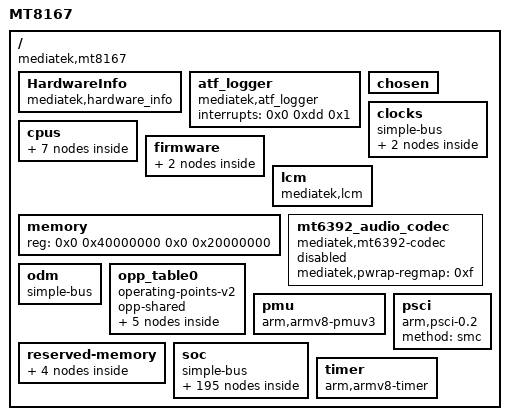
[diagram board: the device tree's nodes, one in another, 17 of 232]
/dts-v1/;

/ {
	#address-cells = <0x2>;
	#size-cells = <0x2>;
	compatible = "mediatek,mt8167";
	interrupt-parent = <0x1>;
	model = "MT8167";

	HardwareInfo {
		compatible = "mediatek,hardware_info";
		linux,phandle = <0xa5>;
		phandle = <0xa5>;
		status = "ok";
	};

	__symbols__ {
		CLUSTER_SLEEP_0 = "/cpus/idle-states/cluster-sleep-0";
		CPU_SLEEP_0_0 = "/cpus/idle-states/cpu-sleep-0-0";
		HardwareInfo = "/HardwareInfo";
		ac108gpio = "/soc/ac108gpio";
		accdet = "/soc/accdet@1001b000";
		afe = "/soc/audio-controller@11140000";
		alsps = "/soc/als_ps@0";
		android = "/firmware/android";
		apmixedsys = "/soc/apmixedsys@10018000";
		atf_reserved_memory = "/reserved-memory/atf-reserved-memory";
		audiotop = "/soc/audiotop@11140000";
		auxadc = "/soc/auxadc@11003000";
		bat_comm = "/soc/bat_comm";
		bat_meter = "/soc/bat_meter";
		btif = "/soc/btif@1100e000";
		chipid = "/soc/chipid@08000000";
		clk26m = "/clocks/clk26m";
		clk32k = "/clocks/clk32k";
		cluster0_opp = "/opp_table0";
		consys = "/soc/consys@18070000";
		cpu0 = "/cpus/cpu@0";
		cpu1 = "/cpus/cpu@1";
		cpu2 = "/cpus/cpu@2";
		cpu3 = "/cpus/cpu@3";
		ddrphy = "/soc/ddrphy@10211000";
		disp_aal = "/soc/disp_aal@1400e000";
		disp_ccorr = "/soc/disp_ccorr@1400d000";
		disp_color = "/soc/disp_color@1400c000";
		disp_dither = "/soc/disp_dither@14010000";
		disp_dpi0 = "/soc/disp_dpi0@14013000";
		disp_dpi1 = "/soc/disp_dpi1@14019000";
		disp_dsi0 = "/soc/disp_dsi0@14012000";
		disp_gamma = "/soc/disp_gamma@1400f000";
		disp_lvds_ana = "/soc/disp_lvds_ana@14018800";
		disp_lvds_tx = "/soc/disp_lvds_tx@1401a200";
		disp_ovl0 = "/soc/disp_ovl0@14007000";
		disp_pwm0 = "/soc/disp_pwm0@1100f000";
		disp_rdma0 = "/soc/disp_rdma0@14009000";
		disp_rdma1 = "/soc/disp_rdma1@1400a000";
		disp_wdma0 = "/soc/disp_wdma0@1400b000";
		dispsys = "/soc/mt8167-dispsys";
		dramc_nao = "/soc/dramc_nao@10206000";
		dramco = "/soc/dramco@10207000";
		emi = "/soc/emi@10205000";
		extd_drv = "/soc/extd_drv@0";
		firmware = "/firmware";
		flashlight_core = "/soc/flashlight_core";
		flashlights_lm3642 = "/soc/flashlights_lm3642";
		fstab = "/firmware/android/fstab";
		gce = "/soc/gce@1020a000";
		gic = "/soc/interrupt-controller@10310000";
		gyro = "/soc/gyroscope@0";
		hdmi0 = "/soc/hdmi@1401b000";
		i2c0 = "/soc/i2c@11009000";
		i2c1 = "/soc/i2c@1100a000";
		i2c2 = "/soc/i2c@1100b000";
		ice = "/soc/ice_debug";
		imgsys = "/soc/imgsys@15000000";
		infracfg = "/soc/infracfg@10001000";
		iommu = "/soc/m4u@10203000";
		isp_display = "/soc/isp_display";
		ispsys = "/soc/ispsys@15000000";
		kd_camera_hw1 = "/soc/camera1@15008000";
		kd_camera_hw2 = "/soc/camera2@15008000";
		keypad = "/soc/keypad@10002000";
		larb0 = "/soc/larb@14016000";
		larb1 = "/soc/larb@15001000";
		larb2 = "/soc/larb@16010000";
		lcm = "/lcm";
		lcm_gpio = "/soc/lcm_gpio@0";
		led0 = "/soc/led@0";
		led1 = "/soc/led@1";
		led2 = "/soc/led@2";
		led3 = "/soc/led@3";
		led4 = "/soc/led@4";
		led5 = "/soc/led@5";
		led6 = "/soc/led@6";
		mcucfg = "/soc/mcucfg@10200000";
		mdp_rdma = "/soc/mdp_rdma@14001000";
		mdp_rsz0 = "/soc/mdp_rsz0@14002000";
		mdp_rsz1 = "/soc/mdp_rsz1@14003000";
		mdp_tdshp = "/soc/mdp_tdshp@14006000";
		mdp_wdma = "/soc/mdp_wdma@14004000";
		mdp_wrot = "/soc/mdp_wrot@14005000";
		met_smi = "/soc/met_smi@14017000";
		mfg = "/soc/clark@13000000";
		mfg_2d = "/soc/mfgsys-2d";
		mfg_async = "/soc/mfgsys-async";
		mfgcfg = "/soc/mfgcfg@13ffe000";
		mipi_tx0 = "/soc/mipi_dphy@14018000";
		mm_mutex = "/soc/mm_mutex@14015000";
		mmc0 = "/soc/mmc@11120000";
		mmc1 = "/soc/mmc@11130000";
		mmc2 = "/soc/sdio@11170000";
		mmsys = "/soc/mmsys@14000000";
		mt6392_audio_codec = "/mt6392_audio_codec";
		mt6392_vadc18_reg = "/soc/pwrap@1000f000/mt6392/mt6392regulator/ldo_vadc18";
		mt6392_vaud22_reg = "/soc/pwrap@1000f000/mt6392/mt6392regulator/ldo_vaud22";
		mt6392_vaud28_reg = "/soc/pwrap@1000f000/mt6392/mt6392regulator/ldo_vaud28";
		mt6392_vcama_reg = "/soc/pwrap@1000f000/mt6392/mt6392regulator/ldo_vcama";
		mt6392_vcamaf_reg = "/soc/pwrap@1000f000/mt6392/mt6392regulator/ldo_vcamaf";
		mt6392_vcamd_reg = "/soc/pwrap@1000f000/mt6392/mt6392regulator/ldo_vcamd";
		mt6392_vcamio_reg = "/soc/pwrap@1000f000/mt6392/mt6392regulator/ldo_vcamio";
		mt6392_vcn18_reg = "/soc/pwrap@1000f000/mt6392/mt6392regulator/ldo_vcn18";
		mt6392_vcn35_reg = "/soc/pwrap@1000f000/mt6392/mt6392regulator/ldo_vcn35";
		mt6392_vcore_reg = "/soc/pwrap@1000f000/mt6392/mt6392regulator/buck_vcore";
		mt6392_vefuse_reg = "/soc/pwrap@1000f000/mt6392/mt6392regulator/ldo_vefuse";
		mt6392_vemc3v3_reg = "/soc/pwrap@1000f000/mt6392/mt6392regulator/ldo_vemc3v3";
		mt6392_vgp1_reg = "/soc/pwrap@1000f000/mt6392/mt6392regulator/ldo_vgp1";
		mt6392_vgp2_reg = "/soc/pwrap@1000f000/mt6392/mt6392regulator/ldo_vgp2";
		mt6392_vio18_reg = "/soc/pwrap@1000f000/mt6392/mt6392regulator/ldo_vio18";
		mt6392_vio28_reg = "/soc/pwrap@1000f000/mt6392/mt6392regulator/ldo_vio28";
		mt6392_vm25_reg = "/soc/pwrap@1000f000/mt6392/mt6392regulator/ldo_vm25";
		mt6392_vm_reg = "/soc/pwrap@1000f000/mt6392/mt6392regulator/ldo_vm";
		mt6392_vmc_reg = "/soc/pwrap@1000f000/mt6392/mt6392regulator/ldo_vmc";
		mt6392_vmch_reg = "/soc/pwrap@1000f000/mt6392/mt6392regulator/ldo_vmch";
		mt6392_vproc_reg = "/soc/pwrap@1000f000/mt6392/mt6392regulator/buck_vproc";
		mt6392_vsys_reg = "/soc/pwrap@1000f000/mt6392/mt6392regulator/buck_vsys";
		mt6392_vusb_reg = "/soc/pwrap@1000f000/mt6392/mt6392regulator/ldo_vusb";
		mt6392_vxo22_reg = "/soc/pwrap@1000f000/mt6392/mt6392regulator/ldo_vxo22";
		mt6392keys = "/soc/pwrap@1000f000/mt6392/mt6392keys";
		mt6392pmic = "/soc/pwrap@1000f000/mt6392/mt6392pmic";
		mt6392regulator = "/soc/pwrap@1000f000/mt6392/mt6392regulator";
		mtkfb = "/soc/mtkfb@0";
		nfi = "/soc/nfi@11001000";
		nfiecc = "/soc/nfiecc@11002000";
		odm = "/odm";
		pio = "/soc/pinctrl@10005000";
		pio6392 = "/soc/pwrap@1000f000/mt6392/pinctrl@c000";
		pmic = "/soc/pwrap@1000f000/mt6392";
		ptp_od = "/soc/ptp_od@1100d000";
		pwm = "/soc/pwm@11008000";
		pwrap = "/soc/pwrap@1000f000";
		reserved_memory = "/reserved-memory";
		scpsys = "/soc/scpsys@10006000";
		smi_common = "/soc/smi@14017000";
		spi = "/soc/spi@1100c000";
		sys_cirq = "/soc/sys_cirq@10202000";
		syscfg_pctl_a = "/soc/syscfg_pctl_a@10005000";
		sysirq = "/soc/intpol-controller@10200620";
		systracker = "/soc/systracker@1020b000";
		thermal = "/soc/thermal@1100d000";
		timer = "/soc/timer@10008000";
		topckgen = "/soc/topckgen@10000000";
		toprgu = "/soc/toprgu@10007000";
		touch = "/soc/touch@";
		typec = "/soc/pwrap@1000f000/mt6392/typec";
		uart0 = "/soc/uart0@11005000";
		uart0_gpio_def_cfg = "/soc/pinctrl@10005000/uart0gpiodefault";
		uart0_rx_clr_cfg = "/soc/pinctrl@10005000/uart0_rx_clear";
		uart0_rx_set_cfg = "/soc/pinctrl@10005000/uart0_rx_set";
		uart0_tx_clr_cfg = "/soc/pinctrl@10005000/uart0_tx_clear";
		uart0_tx_set_cfg = "/soc/pinctrl@10005000/uart0_tx_set";
		uart1 = "/soc/uart1@11006000";
		uart1_gpio_def_cfg = "/soc/pinctrl@10005000/uart1gpiodefault";
		uart1_rx_clr_cfg = "/soc/pinctrl@10005000/uart1_rx_clear";
		uart1_rx_set_cfg = "/soc/pinctrl@10005000/uart1_rx_set";
		uart1_tx_clr_cfg = "/soc/pinctrl@10005000/uart1_tx_clear";
		uart1_tx_set_cfg = "/soc/pinctrl@10005000/uart1_tx_set";
		uart2 = "/soc/uart2@11007000";
		uart2_gpio_def_cfg = "/soc/pinctrl@10005000/uart2gpiodefault";
		uart2_rx_clr_cfg = "/soc/pinctrl@10005000/uart2_rx_clear";
		uart2_rx_set_cfg = "/soc/pinctrl@10005000/uart2_rx_set";
		uart2_tx_clr_cfg = "/soc/pinctrl@10005000/uart2_tx_clear";
		uart2_tx_set_cfg = "/soc/pinctrl@10005000/uart2_tx_set";
		usb0 = "/soc/usb@11100000";
		usb1 = "/soc/usb@11190000";
		vdecsys = "/soc/vdecsys@16000000";
		vencsys = "/soc/vencsys@15000000";
		xo = "/soc/xo@10210000";
	};

	atf_logger {
		compatible = "mediatek,atf_logger";
		interrupts = <0x0 0xdd 0x1>;
	};

	chosen {
		bootargs = "console=ttyS0,921600n1 root=/dev/ram initrd=0x44000200,0x200000";
	};

	clocks {
		#address-cells = <0x2>;
		#size-cells = <0x2>;
		compatible = "simple-bus";
		ranges;

		clk26m {
			#clock-cells = <0x0>;
			clock-frequency = <0x18cba80>;
			compatible = "fixed-clock";
			linux,phandle = <0x30>;
			phandle = <0x30>;
		};

		clk32k {
			#clock-cells = <0x0>;
			clock-frequency = <0x7d00>;
			compatible = "fixed-clock";
			linux,phandle = <0xd>;
			phandle = <0xd>;
		};
	};

	cpus {
		#address-cells = <0x1>;
		#size-cells = <0x0>;

		cpu@0 {
			clock-frequency = "M|m";
			clock-names = "cpu", "intermediate", "armpll";
			clocks = <0x4 0x0 0x5 0x8 0x6 0x0>;
			compatible = "arm,cortex-a53";
			cpu-idle-states = <0x2 0x2 0x3 0x3 0x3>;
			device_type = "cpu";
			enable-method = "psci";
			linux,phandle = <0x8>;
			operating-points-v2 = <0x7>;
			phandle = <0x8>;
			reg = <0x0>;
		};

		cpu@1 {
			clock-frequency = "M|m";
			clock-names = "cpu", "intermediate", "armpll";
			clocks = <0x4 0x0 0x5 0x8 0x6 0x0>;
			compatible = "arm,cortex-a53";
			cpu-idle-states = <0x2 0x2 0x3 0x3 0x3>;
			device_type = "cpu";
			enable-method = "psci";
			linux,phandle = <0x9>;
			operating-points-v2 = <0x7>;
			phandle = <0x9>;
			reg = <0x1>;
		};

		cpu@2 {
			clock-frequency = "M|m";
			clock-names = "cpu", "intermediate", "armpll";
			clocks = <0x4 0x0 0x5 0x8 0x6 0x0>;
			compatible = "arm,cortex-a53";
			cpu-idle-states = <0x2 0x2 0x3 0x3 0x3>;
			device_type = "cpu";
			enable-method = "psci";
			linux,phandle = <0xa>;
			operating-points-v2 = <0x7>;
			phandle = <0xa>;
			reg = <0x2>;
		};

		cpu@3 {
			clock-frequency = "M|m";
			clock-names = "cpu", "intermediate", "armpll";
			clocks = <0x4 0x0 0x5 0x8 0x6 0x0>;
			compatible = "arm,cortex-a53";
			cpu-idle-states = <0x2 0x2 0x3 0x3 0x3>;
			device_type = "cpu";
			enable-method = "psci";
			linux,phandle = <0xb>;
			operating-points-v2 = <0x7>;
			phandle = <0xb>;
			reg = <0x3>;
		};

		idle-states {
			entry-method = "arm,psci";

			cluster-sleep-0 {
				arm,psci-suspend-param = <0x2010000>;
				compatible = "arm,idle-state";
				entry-latency-us = <0x320>;
				exit-latency-us = <0x3e8>;
				linux,phandle = <0x2>;
				min-residency-us = <0x7d0>;
				phandle = <0x2>;
			};

			cpu-sleep-0-0 {
				arm,psci-suspend-param = <0x10000>;
				compatible = "arm,idle-state";
				entry-latency-us = <0x258>;
				exit-latency-us = <0x258>;
				linux,phandle = <0x3>;
				min-residency-us = <0x4b0>;
				phandle = <0x3>;
			};
		};
	};

	firmware {
		linux,phandle = <0xa7>;
		phandle = <0xa7>;

		android {
			compatible = "android,firmware";
			linux,phandle = <0xa8>;
			phandle = <0xa8>;

			fstab {
				compatible = "android,fstab";
				linux,phandle = <0xa9>;
				phandle = <0xa9>;
			};
		};
	};

	lcm {
		compatible = "mediatek,lcm";
		linux,phandle = <0xa4>;
		phandle = <0xa4>;
	};

	memory {
		device_type = "memory";
		reg = <0x0 0x40000000 0x0 0x20000000>;
	};

	mt6392_audio_codec {
		compatible = "mediatek,mt6392-codec";
		linux,phandle = <0xa6>;
		mediatek,pwrap-regmap = <0xf>;
		phandle = <0xa6>;
		status = "disabled";
	};

	odm {
		compatible = "simple-bus";
		linux,phandle = <0xaa>;
		phandle = <0xaa>;
	};

	opp_table0 {
		compatible = "operating-points-v2";
		linux,phandle = <0x7>;
		opp-shared;
		phandle = <0x7>;

		opp00 {
			opp-hz = <0x0 0x23a4c180>;
			opp-microvolt = <0x118c30>;
		};

		opp01 {
			opp-hz = <0x0 0x2c8df1e0>;
			opp-microvolt = <0x118c30>;
		};

		opp02 {
			opp-hz = <0x0 0x3dfd2400>;
			opp-microvolt = <0x124f80>;
		};

		opp03 {
			opp-hz = <0x0 0x47498300>;
			opp-microvolt = <0x1312d0>;
		};

		opp04 {
			opp-hz = <0x0 0x4d7c6d00>;
			opp-microvolt = <0x13d620>;
		};
	};

	pmu {
		compatible = "arm,armv8-pmuv3", "arm,cortex-a7-pmu";
		interrupt-affinity = <0x8 0x9 0xa 0xb>;
		interrupts = <0x0 0x4 0x8 0x0 0x5 0x8 0x0 0x6 0x8 0x0 0x7 0x8>;
	};

	psci {
		compatible = "arm,psci-0.2";
		method = "smc";
	};

	reserved-memory {
		#address-cells = <0x2>;
		#size-cells = <0x2>;
		linux,phandle = <0x2e>;
		phandle = <0x2e>;
		ranges;

		atf-reserved-memory {
			compatible = "mediatek,mt8167-atf-reserved-memory";
			linux,phandle = <0x2f>;
			no-map;
			phandle = <0x2f>;
			reg = <0x0 0x54600000 0x0 0x30000>;
		};

		minirdump-reserved-memory {
			compatible = "mediatek,minirdump";
			reg = <0x0 0x544f0000 0x0 0x10000>;
		};

		pstore-reserved-memory {
			compatible = "mediatek,pstore";
			reg = <0x0 0x54410000 0x0 0xe0000>;
		};

		ram_console-reserved-memory {
			compatible = "mediatek,ram_console";
			reg = <0x0 0x54400000 0x0 0x10000>;
		};
	};

	soc {
		#address-cells = <0x2>;
		#size-cells = <0x2>;
		compatible = "simple-bus";
		ranges;

		BAT_NOTIFY {
			compatible = "mediatek,bat_notify";
		};

		ac108gpio {
			compatible = "MicArray_gpio";
			linux,phandle = <0x99>;
			phandle = <0x99>;
			reg_1v8_gpio = <0x24 0xc 0x1>;
			reg_3v3_gpio = <0x24 0xd 0x1>;
		};

		accdet@1001b000 {
			compatible = "mediatek,mt8167-accdet";
			linux,phandle = <0x50>;
			phandle = <0x50>;
			reg = <0x0 0x1001b000 0x0 0x1000>;
			status = "disabled";
		};

		als_ps@0 {
			compatible = "mediatek,als_ps";
			linux,phandle = <0x90>;
			phandle = <0x90>;
		};

		apmixedsys@10018000 {
			#clock-cells = <0x1>;
			compatible = "mediatek,mt8167-apmixedsys", "syscon";
			linux,phandle = <0x6>;
			phandle = <0x6>;
			reg = <0x0 0x10018000 0x0 0x710>;
		};

		audio-controller@11140000 {
			assigned-clock-parents = <0x5 0x29 0x5 0x2d 0x5 0x91 0x5 0x94>;
			assigned-clocks = <0x5 0xbb 0x5 0xbc 0x5 0xbd 0x5 0xbe>;
			clock-names = "top_pdn_audio", "apll12_div0", "apll12_div1", "apll12_div2", "apll12_div3", "apll12_div4", "apll12_div4b", "apll12_div5", "apll12_div5b", "apll12_div6", "spdif_in", "engen1", "engen2", "aud1", "aud2", "i2s0_m_sel", "i2s1_m_sel", "i2s2_m_sel", "i2s3_m_sel", "i2s4_m_sel", "i2s5_m_sel", "spdif_b_sel";
			clocks = <0x5 0x5b 0x5 0x95 0x5 0x96 0x5 0x97 0x5 0x98 0x5 0x99 0x5 0x9a 0x5 0x9b 0x5 0x9c 0x5 0x9d 0x5 0x8a 0x5 0x86 0x5 0x87 0x5 0x84 0x5 0x85 0x5 0xc0 0x5 0xc1 0x5 0xc2 0x5 0xc3 0x5 0xc4 0x5 0xc5 0x5 0xc6>;
			compatible = "mediatek,mt8167-afe-pcm";
			interrupts = <0x0 0x78 0x8>;
			linux,phandle = <0x68>;
			phandle = <0x68>;
			reg = <0x0 0x11140000 0x0 0x1000 0x0 0x11141000 0x0 0x9000>;
		};

		audiotop@11140000 {
			#clock-cells = <0x1>;
			compatible = "mediatek,mt8167-audiotop", "syscon";
			linux,phandle = <0x6d>;
			phandle = <0x6d>;
			reg = <0x0 0x11140000 0x0 0x1000>;
		};

		auxadc@11003000 {
			clock-names = "auxadc-main", "auxadc1", "auxadc2", "auxadc-tp";
			clocks = <0x5 0x5f 0x5 0x47 0x5 0x51 0x5 0x60>;
			compatible = "mediatek,mt8167-auxadc";
			interrupts = <0x0 0x4b 0x2>;
			linux,phandle = <0x23>;
			phandle = <0x23>;
			reg = <0x0 0x11003000 0x0 0x1000>;
		};

		barometer@0 {
			compatible = "mediatek,barometer";
		};

		bat_comm {
			compatible = "mediatek,battery";
			linux,phandle = <0x9d>;
			phandle = <0x9d>;
		};

		bat_meter {
			compatible = "mediatek,bat_meter";
			linux,phandle = <0x9c>;
			phandle = <0x9c>;
		};

		batchsensor@0 {
			compatible = "mediatek,batchsensor";
		};

		btcvsd@10001000 {
			compatible = "mediatek,audio_bt_cvsd";
			interrupts = <0x0 0xc2 0x8>;
			offset = <0xc00 0x2 0xfd0 0xfd4 0xfd8>;
			reg = <0x0 0x10001000 0x0 0x1000 0x0 0x18000000 0x0 0x10000 0x0 0x18080000 0x0 0x8000>;
		};

		btif@1100e000 {
			clock-names = "btifc", "apdmac";
			clocks = <0x5 0x4e 0x5 0x44>;
			compatible = "mediatek,btif";
			interrupts = <0x0 0x6b 0x8 0x0 0x5e 0x8 0x0 0x5f 0x8>;
			linux,phandle = <0x65>;
			phandle = <0x65>;
			reg = <0x0 0x1100e000 0x0 0x1000 0x0 0x11000380 0x0 0x80 0x0 0x11000400 0x0 0x80>;
		};

		camera1@15008000 {
			clock-names = "TOP_CAMTG_SEL", "TOP_CAM_MIPI_26M", "TOP_CAMTG", "TOP_CAM_TG_48M", "TOP_CAM_TG_208M";
			clocks = <0x5 0xa4 0x5 0x40 0x5 0x3d 0x5 0x28 0x5 0x1c>;
			compatible = "mediatek,mt8167-camera_hw";
			linux,phandle = <0x8c>;
			phandle = <0x8c>;
			reg = <0x0 0x15008000 0x0 0x1000>;
		};

		camera2@15008000 {
			compatible = "mediatek,mt8167-camera_hw2";
			linux,phandle = <0x8d>;
			phandle = <0x8d>;
			reg = <0x0 0x15008000 0x0 0x1000>;
		};

		chipid@08000000 {
			compatible = "mediatek,chipid";
			linux,phandle = <0x31>;
			phandle = <0x31>;
			reg = <0x0 0x8000000 0x0 0x4 0x0 0x8000004 0x0 0x4 0x0 0x8000008 0x0 0x4 0x0 0x800000c 0x0 0x4>;
		};

		clark@13000000 {
			clock-frequency = <0x17d78400>;
			clock-names = "mfg_mm_in_sel", "mfg_axi_in_sel", "mfg_slow_in_sel", "top_slow", "top_axi", "top_mm", "slow_clk26m", "bus_univpll_d24", "bus_mainpll_d11", "engine_csw_mux";
			clocks = <0x5 0xae 0x5 0xb9 0x5 0xba 0x5 0x83 0x5 0x82 0x5 0x3e 0x5 0x31 0x5 0x1e 0x5 0xc 0x5 0xa2>;
			compatible = "mediatek,mt8167-clark";
			interrupt-names = "RGX";
			interrupts = <0x0 0xb9 0x8>;
			linux,phandle = <0x69>;
			phandle = <0x69>;
			power-domains = <0x25 0x6>;
			reg = <0x0 0x13000000 0x0 0x80000 0x0 0x13ffe000 0x0 0x1000>;
		};

		consys@18070000 {
			compatible = "mediatek,mt8167-consys";
			interrupts = <0x0 0xc3 0x8 0x0 0xc5 0x8>;
			linux,phandle = <0x8e>;
			phandle = <0x8e>;
			power-domains = <0x25 0x3>;
			reg = <0x0 0x18070000 0x0 0x200 0x0 0x10000000 0x0 0x2000>;
			reset-names = "connsys";
			resets = <0x29 0xc>;
			status = "disabled";
		};

		ddrphy@10211000 {
			compatible = "mediatek,mt8167-ddrphy", "mediatek,ddrphy";
			linux,phandle = <0x57>;
			phandle = <0x57>;
			reg = <0x0 0x10211000 0x0 0x1000>;
		};

		devapc@10204000 {
			compatible = "mediatek,mt8167-devapc";
			interrupts = <0x0 0x72 0x8>;
			reg = <0x0 0x10204000 0x0 0x1000>;
		};

		devapc_ao@10010000 {
			compatible = "mediatek,mt8167-devapc_ao";
			reg = <0x0 0x10010000 0x0 0x1000>;
		};

		disp_aal@1400e000 {
			compatible = "mediatek,mt8167-disp_aal";
			interrupts = <0x0 0xa7 0x8>;
			linux,phandle = <0x7d>;
			phandle = <0x7d>;
			reg = <0x0 0x1400e000 0x0 0x1000>;
		};

		disp_ccorr@1400d000 {
			compatible = "mediatek,mt8167-disp_ccorr";
			interrupts = <0x0 0xa6 0x8>;
			linux,phandle = <0x7c>;
			phandle = <0x7c>;
			reg = <0x0 0x1400d000 0x0 0x1000>;
		};

		disp_color@1400c000 {
			compatible = "mediatek,mt8167-disp_color";
			interrupts = <0x0 0xa5 0x8>;
			linux,phandle = <0x7b>;
			phandle = <0x7b>;
			reg = <0x0 0x1400c000 0x0 0x1000>;
		};

		disp_dither@14010000 {
			compatible = "mediatek,mt8167-disp_dither";
			interrupts = <0x0 0xa9 0x8>;
			linux,phandle = <0x7f>;
			phandle = <0x7f>;
			reg = <0x0 0x14010000 0x0 0x1000>;
		};

		disp_dpi0@14013000 {
			compatible = "mediatek,mt8167-disp_dpi0";
			interrupts = <0x0 0xac 0x8>;
			linux,phandle = <0x81>;
			phandle = <0x81>;
			reg = <0x0 0x14013000 0x0 0x1000>;
		};

		disp_dpi1@14019000 {
			compatible = "mediatek,mt8167-disp_dpi1";
			interrupts = <0x0 0xae 0x8>;
			linux,phandle = <0x85>;
			phandle = <0x85>;
			reg = <0x0 0x14019000 0x0 0x1000>;
		};

		disp_dsi0@14012000 {
			compatible = "mediatek,mt8167-disp_dsi0";
			interrupts = <0x0 0xab 0x8>;
			linux,phandle = <0x80>;
			phandle = <0x80>;
			reg = <0x0 0x14012000 0x0 0x1000>;
		};

		disp_gamma@1400f000 {
			compatible = "mediatek,mt8167-disp_gamma";
			interrupts = <0x0 0xa8 0x8>;
			linux,phandle = <0x7e>;
			phandle = <0x7e>;
			reg = <0x0 0x1400f000 0x0 0x1000>;
		};

		disp_lvds_ana@14018800 {
			compatible = "mediatek,mt8167-disp_lvds_ana";
			linux,phandle = <0x84>;
			phandle = <0x84>;
			reg = <0x0 0x14018800 0x0 0x1c>;
		};

		disp_lvds_tx@1401a200 {
			compatible = "mediatek,mt8167-disp_lvds_tx";
			linux,phandle = <0x86>;
			phandle = <0x86>;
			reg = <0x0 0x1401a200 0x0 0x64>;
		};

		disp_ovl0@14007000 {
			compatible = "mediatek,mt8167-disp_ovl0";
			interrupts = <0x0 0xa0 0x8>;
			linux,phandle = <0x77>;
			phandle = <0x77>;
			reg = <0x0 0x14007000 0x0 0x1000>;
		};

		disp_pwm0@1100f000 {
			compatible = "mediatek,mt8167-disp_pwm";
			linux,phandle = <0x66>;
			phandle = <0x66>;
			reg = <0x0 0x1100f000 0x0 0x1000>;
		};

		disp_rdma0@14009000 {
			compatible = "mediatek,mt8167-disp_rdma0";
			interrupts = <0x0 0xa2 0x8>;
			linux,phandle = <0x78>;
			phandle = <0x78>;
			reg = <0x0 0x14009000 0x0 0x1000>;
		};

		disp_rdma1@1400a000 {
			compatible = "mediatek,mt8167-disp_rdma1";
			interrupts = <0x0 0xa3 0x8>;
			linux,phandle = <0x79>;
			phandle = <0x79>;
			reg = <0x0 0x1400a000 0x0 0x1000>;
		};

		disp_wdma0@1400b000 {
			compatible = "mediatek,mt8167-disp_wdma0";
			interrupts = <0x0 0xa4 0x8>;
			linux,phandle = <0x7a>;
			phandle = <0x7a>;
			reg = <0x0 0x1400b000 0x0 0x1000>;
		};

		dramc_nao@10206000 {
			compatible = "mediatek,mt8167-dramc_nao", "mediatek,dramc_nao";
			linux,phandle = <0x55>;
			phandle = <0x55>;
			reg = <0x0 0x10206000 0x0 0x1000>;
		};

		dramco@10207000 {
			compatible = "mediatek,mt8167-dramco";
			linux,phandle = <0x33>;
			phandle = <0x33>;
			reg = <0x0 0x10207000 0x0 0x1000>;
		};

		dumchar {
			compatible = "mediatek,mt8167-dummy_char";
		};

		emi@10205000 {
			compatible = "mediatek,mt8167-emi", "mediatek,emi";
			interrupts = <0x0 0x74 0x4>;
			linux,phandle = <0x52>;
			phandle = <0x52>;
			reg = <0x0 0x10205000 0x0 0x1000>;
		};

		extd_drv@0 {
			compatible = "mediatek,extd_dev";
			linux,phandle = <0x9e>;
			phandle = <0x9e>;
		};

		fhctl@10018f00 {
			compatible = "mediatek,mt8167-fhctl";
			reg = <0x0 0x10018f00 0x0 0x100>;
		};

		flashlight_core {
			compatible = "mediatek,flashlight_core";
			linux,phandle = <0x9f>;
			phandle = <0x9f>;
		};

		flashlights_lm3642 {
			compatible = "mediatek,flashlights_lm3642";
			linux,phandle = <0xa0>;
			phandle = <0xa0>;
		};

		g3d_iommu@13005000 {
			cell-index = <0x2>;
			compatible = "mediatek,mt8167-g3d_iommu";
			interrupts = <0x0 0xe2 0x8>;
			reg = <0x0 0x13005000 0x0 0x1000>;
		};

		gce@1020a000 {
			apxgpt2_count = <0x10008028>;
			audio_base = <0x11220000 0x12 0xffff0000>;
			buf_underrun_event_0 = <0x30>;
			buf_underrun_event_1 = <0x31>;
			clock-names = "MT_CG_INFRA_GCE", "MT_CG_DISP0_SMI_COMMON", "MT_CG_DISP0_SMI_LARB0", "MT_CG_DISP0_CAM_MDP", "MT_CG_DISP0_MDP_RDMA", "MT_CG_DISP0_MDP_RSZ0", "MT_CG_DISP0_MDP_RSZ1", "MT_CG_DISP0_MDP_TDSHP", "MT_CG_DISP0_MDP_WROT", "MT_CG_DISP0_MDP_WDMA";
			clocks = <0x5 0x64 0x13 0x0 0x13 0x1 0x13 0x2 0x13 0x3 0x13 0x4 0x13 0x5 0x13 0x6 0x13 0x8 0x13 0x7>;
			compatible = "mediatek,mt8167-gce";
			conn_peri_base = <0x18000000 0x7 0xffff0000>;
			disp_aal_frame_done = <0x20>;
			disp_aal_sof = <0xd>;
			disp_ccorr_frame_done = <0x1e>;
			disp_ccorr_sof = <0xb>;
			disp_color_frame_done = <0x1f>;
			disp_color_sof = <0xc>;
			disp_dither_base = <0x14010000 0x2 0xffff0000>;
			disp_dither_frame_done = <0x22>;
			disp_dither_sof = <0xf>;
			disp_dpi0_frame_done = <0x24>;
			disp_dpi1_frame_done = <0x25>;
			disp_gamma_frame_done = <0x21>;
			disp_gamma_sof = <0xe>;
			disp_mutex_reg = <0x14015000 0x1000>;
			disp_ovl0_frame_done = <0x19>;
			disp_ovl0_sof = <0x6>;
			disp_pwm0_sof = <0x11>;
			disp_rdma0_frame_done = <0x1b>;
			disp_rdma0_sof = <0x8>;
			disp_rdma1_frame_done = <0x1c>;
			disp_rdma1_sof = <0x9>;
			disp_ufoe_frame_done = <0x23>;
			disp_ufoe_sof = <0x10>;
			disp_wdma0_frame_done = <0x1d>;
			disp_wdma0_sof = <0xa>;
			g3d_config_base = <0x13000000 0x0 0xffff0000>;
			gcpu_base = <0x1020d000 0xf 0xffff0000>;
			imgsys_base = <0x15000000 0x4 0xffff0000>;
			infra_na3_base = <0x10030000 0xb 0xffff0000>;
			infra_na4_base = <0x10040000 0xc 0xffff0000>;
			interrupts = <0x0 0x7d 0x8 0x0 0x7e 0x8>;
			isp_frame_done_p2_0 = <0x43>;
			isp_frame_done_p2_1 = <0x42>;
			kp_base = <0x10010000 0x9 0xffff0000>;
			linux,phandle = <0x58>;
			mcucfg_base = <0x10200000 0xe 0xffff0000>;
			mdp_rdma0_frame_done = <0x12>;
			mdp_rdma0_sof = <0x0>;
			mdp_rsz0_frame_done = <0x13>;
			mdp_rsz0_sof = <0x1>;
			mdp_rsz1_frame_done = <0x14>;
			mdp_rsz1_sof = <0x2>;
			mdp_tdshp_frame_done = <0x15>;
			mdp_tdshp_sof = <0x3>;
			mdp_wdma_frame_done = <0x16>;
			mdp_wdma_sof = <0x4>;
			mdp_wrot_read_frame_done = <0x18>;
			mdp_wrot_sof = <0x5>;
			mdp_wrot_write_frame_done = <0x17>;
			mm_na_base = <0x14020000 0x3 0xffff0000>;
			mmsys_config_base = <0x14000000 0x1 0xffff0000>;
			msdc0_base = <0x11230000 0x13 0xffff0000>;
			msdc1_base = <0x11240000 0x14 0xffff0000>;
			msdc2_base = <0x11250000 0x15 0xffff0000>;
			msdc3_base = <0x11260000 0x16 0xffff0000>;
			phandle = <0x58>;
			pwm_sw_base = <0x1100f000 0x63 0xfffff000>;
			reg = <0x0 0x1020a000 0x0 0x1000>;
			scp_base = <0x10050000 0xd 0xffff0000>;
			scp_sram_base = <0x10020000 0xa 0xffff0000>;
			seninf_cam0_fifo_full = <0x49>;
			stream_done_0 = <0x26>;
			stream_done_1 = <0x27>;
			stream_done_2 = <0x28>;
			stream_done_3 = <0x29>;
			stream_done_4 = <0x2a>;
			stream_done_5 = <0x2b>;
			stream_done_6 = <0x2c>;
			stream_done_7 = <0x2d>;
			stream_done_8 = <0x2e>;
			stream_done_9 = <0x2f>;
			topckgen_base = <0x10000000 0x8 0xffff0000>;
			usb0_base = <0x11200000 0x10 0xffff0000>;
			usb_sif_base = <0x11210000 0x11 0xffff0000>;
			vdec_gcon_base = <0x16000000 0x5 0xffff0000>;
			venc_gcon_base = <0x17000000 0x6 0xffff0000>;
		};

		gps {
			compatible = "mediatek,gps";
		};

		gsensor@0 {
			compatible = "mediatek,gsensor";
		};

		gyroscope@0 {
			compatible = "mediatek,gyroscope";
			linux,phandle = <0x91>;
			phandle = <0x91>;
		};

		hacc@1000a000 {
			clock-names = "main", "second";
			clocks = <0x5 0x57 0x5 0x66>;
			compatible = "mediatek,hacc";
			reg = <0x0 0x1000a000 0x0 0x1000>;
		};

		hdmi@1401b000 {
			clock-names = "clk_ddc", "clk_cec_26m", "clk_cec_32k", "mmsys_hdmi_pixel", "mmsys_hdmi_pll", "mmsys_hdmi_audio", "mmsys_hdmi_spidif";
			clocks = <0x5 0x70 0x5 0x71 0x5 0x72 0x13 0x1e 0x13 0x21 0x13 0x20 0x13 0x1f>;
			compatible = "mediatek,mt8167-hdmitx";
			interrupts = <0x0 0x94 0x8>;
			linux,phandle = <0x87>;
			phandle = <0x87>;
			power-domains = <0x25 0x0>;
			reg = <0x0 0x1401b000 0x0 0x1000 0x0 0x11011000 0x0 0x10 0x0 0x1001a000 0x0 0xbc>;
			status = "disabled";
		};

		hwmsensor@0 {
			compatible = "mediatek,hwmsensor";
		};

		i2c@11009000 {
			#address-cells = <0x1>;
			#size-cells = <0x0>;
			clock-frequency = <0x61a80>;
			clock-names = "main-source", "main-sel", "main", "dma";
			clocks = <0x5 0x39 0x4 0x2 0x5 0x45 0x5 0x44>;
			compatible = "mediatek,mt8167-i2c";
			interrupts = <0x0 0x50 0x8>;
			linux,phandle = <0x5f>;
			phandle = <0x5f>;
			reg = <0x0 0x11009000 0x0 0x90 0x0 0x11000180 0x0 0x80>;
			status = "disabled";
		};

		i2c@1100a000 {
			#address-cells = <0x1>;
			#size-cells = <0x0>;
			clock-names = "main-source", "main-sel", "main", "dma";
			clocks = <0x5 0x39 0x4 0x3 0x5 0x46 0x5 0x44>;
			compatible = "mediatek,mt8167-i2c";
			interrupts = <0x0 0x51 0x8>;
			linux,phandle = <0x60>;
			phandle = <0x60>;
			reg = <0x0 0x1100a000 0x0 0x90 0x0 0x11000200 0x0 0x80>;
			status = "disabled";
		};

		i2c@1100b000 {
			#address-cells = <0x1>;
			#size-cells = <0x0>;
			clock-names = "main-source", "main-sel", "main", "dma";
			clocks = <0x5 0x39 0x4 0x4 0x5 0x52 0x5 0x44>;
			compatible = "mediatek,mt8167-i2c";
			interrupts = <0x0 0x52 0x8>;
			linux,phandle = <0x61>;
			phandle = <0x61>;
			reg = <0x0 0x1100b000 0x0 0x90 0x0 0x11000280 0x0 0x80>;
			status = "disabled";
		};

		ice_debug {
			clock-names = "ice_dbg";
			clocks = <0x5 0x4a>;
			compatible = "mediatek,mt8167-ice_debug", "mediatek,mt8173-ice_debug";
			linux,phandle = <0xa1>;
			phandle = <0xa1>;
		};

		imgsys@15000000 {
			#clock-cells = <0x1>;
			compatible = "mediatek,mt8167-imgsys", "syscon";
			linux,phandle = <0x27>;
			phandle = <0x27>;
			reg = <0x0 0x15000000 0x0 0x1000>;
		};

		infracfg@10001000 {
			#clock-cells = <0x1>;
			compatible = "mediatek,mt8167-infracfg", "syscon";
			linux,phandle = <0x4>;
			phandle = <0x4>;
			reg = <0x0 0x10001000 0x0 0x1000>;
		};

		interrupt-controller@10310000 {
			#interrupt-cells = <0x3>;
			compatible = "arm,gic-400";
			interrupt-controller;
			interrupt-parent = <0xc>;
			interrupts = <0x1 0x9 0xf04>;
			linux,phandle = <0xc>;
			phandle = <0xc>;
			reg = <0x0 0x10310000 0x0 0x1000 0x0 0x10320000 0x0 0x1000 0x0 0x10340000 0x0 0x2000 0x0 0x10360000 0x0 0x2000>;
		};

		intpol-controller@10200620 {
			#interrupt-cells = <0x3>;
			compatible = "mediatek,mt8167-sysirq", "mediatek,mt6577-sysirq";
			interrupt-controller;
			interrupt-parent = <0xc>;
			linux,phandle = <0x1>;
			phandle = <0x1>;
			reg = <0x0 0x10200620 0x0 0x20>;
		};

		isp_display {
			compatible = "mediatek,mt8167-isp_display";
			linux,phandle = <0x89>;
			phandle = <0x89>;
		};

		isp_pipemgr {
			compatible = "mediatek,mt8167-isp_pipemgr";
		};

		isp_sysram {
			compatible = "mediatek,mt8167-isp_sysram";
		};

		ispsys@15000000 {
			clock-names = "IMG_LARB_SMI", "IMG_CAM_SMI", "IMG_CAM_CAM", "IMG_SEN_TG", "IMG_SEN_CAM", "MM_SMI_COMMON";
			clocks = <0x27 0x0 0x27 0x1 0x27 0x2 0x27 0x3 0x27 0x4 0x13 0x0>;
			compatible = "mediatek,mt8167-ispsys";
			interrupts = <0x0 0xb4 0x8 0x0 0xb7 0x8>;
			linux,phandle = <0x8a>;
			mediatek,smilarb = <0x11>;
			phandle = <0x8a>;
			reg = <0x0 0x15004000 0x0 0x9000 0x0 0x15000000 0x0 0x10000 0x0 0x10011000 0x0 0x3000>;
		};

		keypad@10002000 {
			compatible = "mediatek,mt8167-keypad";
			interrupts = <0x0 0x95 0x2>;
			linux,phandle = <0x4f>;
			phandle = <0x4f>;
			reg = <0x0 0x10002000 0x0 0x1000>;
		};

		larb@14016000 {
			clock-names = "apb", "smi";
			clocks = <0x13 0x1 0x13 0x1>;
			compatible = "mediatek,mt8167-smi-larb";
			linux,phandle = <0x10>;
			mediatek,larbid = <0x0>;
			mediatek,smi = <0x26>;
			phandle = <0x10>;
			power-domains = <0x25 0x0>;
			reg = <0x0 0x14016000 0x0 0x1000>;
		};

		larb@15001000 {
			clock-names = "apb", "smi";
			clocks = <0x27 0x0 0x27 0x0>;
			compatible = "mediatek,mt8167-smi-larb";
			linux,phandle = <0x11>;
			mediatek,larbid = <0x1>;
			mediatek,smi = <0x26>;
			phandle = <0x11>;
			power-domains = <0x25 0x2>;
			reg = <0x0 0x15001000 0x0 0x10000>;
		};

		larb@16010000 {
			clock-names = "apb", "smi";
			clocks = <0x28 0x0 0x28 0x1>;
			compatible = "mediatek,mt8167-smi-larb";
			linux,phandle = <0x12>;
			mediatek,larbid = <0x2>;
			mediatek,smi = <0x26>;
			phandle = <0x12>;
			power-domains = <0x25 0x1>;
			reg = <0x0 0x16010000 0x0 0x1000>;
		};

		lcm_gpio@0 {
			compatible = "mediatek,I2C_LCD_BIAS";
			lcm-supply = <0x2b>;
			lcm_gpio_enn = <0x24 0x14 0x0>;
			lcm_gpio_te = <0x24 0x43 0x0>;
			lcm_rst_pin = <0x24 0x42 0x0>;
			linux,phandle = <0x9b>;
			phandle = <0x9b>;
			status = "okay";
		};

		led@0 {
			compatible = "mediatek,red";
			data = <0x0>;
			led_mode = <0x0>;
			linux,phandle = <0x92>;
			phandle = <0x92>;
			pwm_config = <0x0 0x0 0x0 0x0 0x0>;
		};

		led@1 {
			compatible = "mediatek,green";
			data = <0x0>;
			led_mode = <0x0>;
			linux,phandle = <0x93>;
			phandle = <0x93>;
			pwm_config = <0x0 0x0 0x0 0x0 0x0>;
		};

		led@2 {
			compatible = "mediatek,blue";
			data = <0x0>;
			led_mode = <0x0>;
			linux,phandle = <0x94>;
			phandle = <0x94>;
			pwm_config = <0x0 0x0 0x0 0x0 0x0>;
		};

		led@3 {
			compatible = "mediatek,jogball-backlight";
			data = <0x0>;
			led_mode = <0x0>;
			linux,phandle = <0x95>;
			phandle = <0x95>;
			pwm_config = <0x0 0x0 0x0 0x0 0x0>;
		};

		led@4 {
			compatible = "mediatek,keyboard-backlight";
			data = <0x0>;
			led_mode = <0x0>;
			linux,phandle = <0x96>;
			phandle = <0x96>;
			pwm_config = <0x0 0x0 0x0 0x0 0x0>;
		};

		led@5 {
			compatible = "mediatek,button-backlight";
			data = <0x0>;
			led_mode = <0x0>;
			linux,phandle = <0x97>;
			phandle = <0x97>;
			pwm_config = <0x0 0x0 0x0 0x0 0x0>;
		};

		led@6 {
			compatible = "mediatek,lcd-backlight";
			data;
			led_mode = <0x5>;
			linux,phandle = <0x98>;
			phandle = <0x98>;
			pwm_config = <0x0 0x0 0x0 0x0 0x0>;
		};

		m4u@10203000 {
			#iommu-cells = <0x1>;
			cell-index = <0x0>;
			compatible = "mediatek,mt8167-m4u";
			interrupts = <0x0 0x79 0x8>;
			linux,phandle = <0x2d>;
			mediatek,larbs = <0x10 0x11 0x12>;
			phandle = <0x2d>;
			reg = <0x0 0x10203000 0x0 0x1000>;
		};

		mcucfg@10200000 {
			compatible = "mediatek,mt8167-mcucfg", "mediatek,mcucfg", "syscon";
			linux,phandle = <0x51>;
			phandle = <0x51>;
			reg = <0x0 0x10200000 0x0 0x2000>;
		};

		mdp_rdma@14001000 {
			compatible = "mediatek,mt8167-mdp_rdma";
			interrupts = <0x0 0x9a 0x8>;
			linux,phandle = <0x70>;
			phandle = <0x70>;
			reg = <0x0 0x14001000 0x0 0x1000>;
		};

		mdp_rsz0@14002000 {
			compatible = "mediatek,mt8167-mdp_rsz0";
			interrupts = <0x0 0x9b 0x8>;
			linux,phandle = <0x71>;
			phandle = <0x71>;
			reg = <0x0 0x14002000 0x0 0x1000>;
		};

		mdp_rsz1@14003000 {
			compatible = "mediatek,mt8167-mdp_rsz1";
			interrupts = <0x0 0x9c 0x8>;
			linux,phandle = <0x72>;
			phandle = <0x72>;
			reg = <0x0 0x14003000 0x0 0x1000>;
		};

		mdp_tdshp@14006000 {
			compatible = "mediatek,mdp_tdshp";
			interrupts = <0x0 0x9d 0x8>;
			linux,phandle = <0x75>;
			phandle = <0x75>;
			reg = <0x0 0x14006000 0x0 0x1000>;
		};

		mdp_wdma@14004000 {
			compatible = "mediatek,mt8167-mdp_wdma";
			interrupts = <0x0 0x9e 0x8>;
			linux,phandle = <0x73>;
			phandle = <0x73>;
			reg = <0x0 0x14004000 0x0 0x1000>;
		};

		mdp_wrot@14005000 {
			compatible = "mediatek,mt8167-mdp_wrot";
			interrupts = <0x0 0x9f 0x8>;
			linux,phandle = <0x74>;
			phandle = <0x74>;
			reg = <0x0 0x14005000 0x0 0x1000>;
		};

		met_smi@14017000 {
			clock-names = "smi-common", "smi-larb0", "img-larb1", "vdec-larb2";
			clocks = <0x13 0x0 0x13 0x1 0x27 0x0 0x28 0x0>;
			compatible = "mediatek,met_smi";
			linux,phandle = <0x88>;
			phandle = <0x88>;
			reg = <0x0 0x14017000 0x0 0x1000 0x0 0x14016000 0x0 0x1000 0x0 0x15001000 0x0 0x1000 0x0 0x16010000 0x0 0x1000>;
		};

		mfgcfg@13ffe000 {
			#clock-cells = <0x1>;
			compatible = "mediatek,mt8167-mfgcfg", "syscon";
			linux,phandle = <0x6a>;
			phandle = <0x6a>;
			reg = <0x0 0x13ffe000 0x0 0x1000>;
		};

		mfgsys-2d {
			compatible = "mediatek,mt8167-mfg-2d";
			linux,phandle = <0xa3>;
			phandle = <0xa3>;
			power-domains = <0x25 0x5>;
		};

		mfgsys-async {
			compatible = "mediatek,mt8167-mfg-async";
			linux,phandle = <0xa2>;
			phandle = <0xa2>;
			power-domains = <0x25 0x4>;
		};

		mipi_dphy@14018000 {
			compatible = "mediatek,mt8167-disp_mipi_tx";
			linux,phandle = <0x83>;
			phandle = <0x83>;
			reg = <0x0 0x14018000 0x0 0x90>;
		};

		mm_mutex@14015000 {
			compatible = "mediatek,mt8167-disp_mutex";
			interrupts = <0x0 0x99 0x8>;
			linux,phandle = <0x82>;
			phandle = <0x82>;
			reg = <0x0 0x14015000 0x0 0x1000>;
		};

		mmc@11120000 {
			clock-names = "source", "hclk", "source_cg";
			clocks = <0x5 0x53 0x5 0xa1 0x5 0xd9>;
			compatible = "mediatek,mt8167-mmc";
			interrupts = <0x0 0x4e 0x8>;
			linux,phandle = <0x6b>;
			phandle = <0x6b>;
			reg = <0x0 0x11120000 0x0 0x1000>;
			status = "disabled";
		};

		mmc@11130000 {
			clock-names = "source", "hclk", "source_cg";
			clocks = <0x5 0x54 0x5 0xa1 0x5 0xda>;
			compatible = "mediatek,mt8167-mmc";
			interrupts = <0x0 0x4f 0x8>;
			linux,phandle = <0x6c>;
			phandle = <0x6c>;
			reg = <0x0 0x11130000 0x0 0x1000>;
			status = "disabled";
		};

		mmsys@14000000 {
			#clock-cells = <0x1>;
			compatible = "mediatek,mt8167-mmsys", "syscon";
			linux,phandle = <0x13>;
			phandle = <0x13>;
			reg = <0x0 0x14000000 0x0 0x1000>;
		};

		msensor@0 {
			compatible = "mediatek,msensor";
		};

		mt8167-dispsys {
			clock-names = "MMSYS_CLK_FAKE_ENG", "MMSYS_CLK_DISP_OVL0", "MMSYS_CLK_DISP_RDMA0", "MMSYS_CLK_DISP_RDMA1", "MMSYS_CLK_DISP_WDMA0", "MMSYS_CLK_DISP_COLOR", "MMSYS_CLK_DISP_CCORR", "MMSYS_CLK_DISP_AAL", "MMSYS_CLK_DISP_GAMMA", "MMSYS_CLK_DISP_DITHER", "MMSYS_CLK_DISP_UFOE", "MMSYS_CLK_TOP_PWM_MM", "MMSYS_CLK_DISP_PWM", "MMSYS_CLK_DISP_PWM26M", "MMSYS_CLK_DSI_ENGINE", "MMSYS_CLK_DSI_DIGITAL", "MMSYS_CLK_DPI0_PIXEL", "MMSYS_CLK_DPI0_ENGINE", "MMSYS_CLK_LVDS_PIXEL", "MMSYS_CLK_LVDS_CTS", "MMSYS_CLK_DPI1_PIXEL", "MMSYS_CLK_DPI1_ENGINE", "MMSYS_CLK_TOP_MIPI_26M", "MMSYS_CLK_TOP_MIPI_26M_DBG", "MMSYS_CLK_TOP_RG_FDPI0", "MMSYS_CLK_MUX_DPI0_SEL", "MMSYS_APMIXED_LVDSPLL", "MMSYS_CLK_MUX_LVDSPLL_D2", "MMSYS_CLK_MUX_LVDSPLL_D4", "MMSYS_CLK_MUX_LVDSPLL_D8", "MMSYS_CLK_TOP_RG_FDPI1", "MMSYS_CLK_MUX_DPI1_SEL", "MMSYS_APMIXED_TVDPLL", "MMSYS_CLK_MUX_TVDPLL_D2", "MMSYS_CLK_MUX_TVDPLL_D4", "MMSYS_CLK_MUX_TVDPLL_D8", "MMSYS_CLK_MUX_TVDPLL_D16", "MMSYS_CLK_PWM_SEL", "TOP_UNIVPLL_D12";
			clocks = <0x13 0x9 0x13 0xa 0x13 0xb 0x13 0xc 0x13 0xd 0x13 0xe 0x13 0xf 0x13 0x10 0x13 0x11 0x13 0x12 0x13 0x13 0x5 0x3c 0x13 0x14 0x13 0x15 0x13 0x16 0x13 0x17 0x13 0x19 0x13 0x18 0x13 0x1a 0x13 0x1b 0x13 0x1d 0x13 0x1c 0x5 0x33 0x5 0x40 0x5 0x80 0x5 0xb7 0x6 0x7 0x5 0x25 0x5 0x26 0x5 0x27 0x5 0x81 0x5 0xb8 0x6 0x6 0x5 0x35 0x5 0x36 0x5 0x37 0x5 0x38 0x5 0xc7 0x5 0x1d>;
			compatible = "mediatek,mt8167-dispsys";
			linux,phandle = <0x76>;
			mediatek,larb = <0x10>;
			phandle = <0x76>;
		};

		mt_soc_btcvsd_rx_pcm@10001000 {
			compatible = "mediatek,mt_soc_btcvsd_rx_pcm";
		};

		mt_soc_btcvsd_tx_pcm@10001000 {
			compatible = "mediatek,mt_soc_btcvsd_tx_pcm";
		};

		mtee {
			clock-names = "GCPU", "TRNG", "IMG_CLK", "SMI_COMMON", "IMG_SMI";
			clocks = <0x5 0x7b 0x5 0x65 0x27 0x5 0x13 0x0 0x27 0x0>;
			compatible = "mediatek,mtee";
			pm-devs = <0x11 0x26>;
			pm-names = "isp", "disp";
		};

		mtgpufreq {
			compatible = "mediatek,mt8167-gpufreq";
			reg-vgpu-supply = <0x2c>;
		};

		mtkfb@0 {
			compatible = "mediatek,MTKFB";
			linux,phandle = <0x9a>;
			mediatek,larb = <0x10>;
			phandle = <0x9a>;
		};

		nfi@11001000 {
			clock-names = "nfi_hclk", "nfiecc_bclk", "nfi_bclk", "nfi_rgecc", "nfi_2xclk", "nfi_1xclk", "nfi_1xpad_sel", "nfi_2xpad_sel", "nfiecc_sel", "nfiecc_csw_sel", "infra_ahb", "clk_26m", "main_d4", "main_d5", "main_d6", "main_d7", "main_d8", "main_d10", "main_d12";
			clocks = <0x5 0x63 0x5 0x49 0x5 0x48 0x5 0x8e 0x5 0x55 0x5 0x3a 0x5 0xad 0x5 0xac 0x5 0xce 0x5 0xcd 0x5 0xa1 0x5 0x31 0x5 0x9 0x5 0x11 0x5 0xf 0x5 0x15 0x5 0xa 0x5 0x12 0x5 0x10>;
			compatible = "mediatek,mt8167-nfi";
			interrupts = <0x0 0x57 0x8>;
			linux,phandle = <0x59>;
			phandle = <0x59>;
			reg = <0x0 0x11001000 0x0 0x1000>;
			status = "disabled";
		};

		nfiecc@11002000 {
			compatible = "mediatek,mt8167-nfiecc";
			interrupts = <0x0 0x56 0x8>;
			linux,phandle = <0x5a>;
			phandle = <0x5a>;
			reg = <0x0 0x11002000 0x0 0x1000>;
			status = "disabled";
		};

		orientation@0 {
			compatible = "mediatek,orientation";
		};

		pinctrl@10005000 {
			#gpio-cells = <0x2>;
			#interrupt-cells = <0x2>;
			compatible = "mediatek,mt8167-pinctrl";
			gpio-controller;
			interrupt-controller;
			interrupts = <0x0 0x86 0x4>;
			linux,phandle = <0x24>;
			mediatek,pctl-regmap = <0xe>;
			phandle = <0x24>;
			pins-are-numbered;
			reg = <0x0 0x1000b000 0x0 0x1000>;

			uart0_rx_clear {
				linux,phandle = <0x16>;
				phandle = <0x16>;

				pins_cmd_dat {
					output-high;
					pinmux = <0x3e00>;
					slew-rate = <0x1>;
				};
			};

			uart0_rx_set {
				linux,phandle = <0x15>;
				phandle = <0x15>;

				pins_cmd_dat {
					bias-pull-up;
					input-enable;
					pinmux = <0x3e01>;
				};
			};

			uart0_tx_clear {
				linux,phandle = <0x18>;
				phandle = <0x18>;

				pins_cmd_dat {
					output-high;
					pinmux = <0x3f00>;
					slew-rate = <0x1>;
				};
			};

			uart0_tx_set {
				linux,phandle = <0x17>;
				phandle = <0x17>;

				pins_cmd_dat {
					pinmux = <0x3f01>;
				};
			};

			uart0gpiodefault {
				linux,phandle = <0x14>;
				phandle = <0x14>;

				pins_rx {
					bias-pull-up;
					input-enable;
					pinmux = <0x3e01>;
				};

				pins_tx {
					pinmux = <0x3f01>;
				};
			};

			uart1_rx_clear {
				linux,phandle = <0x1b>;
				phandle = <0x1b>;

				pins_cmd_dat {
					output-high;
					pinmux = <0x4000>;
					slew-rate = <0x1>;
				};
			};

			uart1_rx_set {
				linux,phandle = <0x1a>;
				phandle = <0x1a>;

				pins_cmd_dat {
					pinmux = <0x4001>;
				};
			};

			uart1_tx_clear {
				linux,phandle = <0x1d>;
				phandle = <0x1d>;

				pins_cmd_dat {
					output-high;
					pinmux = <0x4100>;
					slew-rate = <0x1>;
				};
			};

			uart1_tx_set {
				linux,phandle = <0x1c>;
				phandle = <0x1c>;

				pins_cmd_dat {
					pinmux = <0x4101>;
				};
			};

			uart1gpiodefault {
				linux,phandle = <0x19>;
				phandle = <0x19>;
			};

			uart2_rx_clear {
				linux,phandle = <0x20>;
				phandle = <0x20>;

				pins_cmd_dat {
					output-high;
					pinmux = <0x2200>;
					slew-rate = <0x1>;
				};
			};

			uart2_rx_set {
				linux,phandle = <0x1f>;
				phandle = <0x1f>;

				pins_cmd_dat {
					pinmux = <0x2201>;
				};
			};

			uart2_tx_clear {
				linux,phandle = <0x22>;
				phandle = <0x22>;

				pins_cmd_dat {
					output-high;
					pinmux = <0x2300>;
					slew-rate = <0x1>;
				};
			};

			uart2_tx_set {
				linux,phandle = <0x21>;
				phandle = <0x21>;

				pins_cmd_dat {
					pinmux = <0x2301>;
				};
			};

			uart2gpiodefault {
				linux,phandle = <0x1e>;
				phandle = <0x1e>;
			};
		};

		pseudo-m4u {
			compatible = "mediatek,mt8167-pseudo-m4u";
			iommus = <0x2d 0x1>;
		};

		pseudo-m4u-larb0 {
			compatible = "mediatek,mt8167-pseudo-port-m4u";
			iommus = <0x2d 0x0 0x2d 0x1 0x2d 0x2 0x2d 0x3 0x2d 0x4 0x2d 0x5 0x2d 0x5 0x2d 0x6 0x2d 0x7>;
			mediatek,larbid = <0x0>;
		};

		pseudo-m4u-larb1 {
			compatible = "mediatek,mt8167-pseudo-port-m4u";
			iommus = <0x2d 0x8 0x2d 0x9 0x2d 0xa 0x2d 0xb 0x2d 0xc 0x2d 0xd 0x2d 0xe 0x2d 0xf 0x2d 0x10 0x2d 0x11 0x2d 0x12 0x2d 0x13 0x2d 0x14>;
			mediatek,larbid = <0x1>;
		};

		pseudo-m4u-larb2 {
			compatible = "mediatek,mt8167-pseudo-port-m4u";
			iommus = <0x2d 0x15 0x2d 0x16 0x2d 0x17 0x2d 0x18 0x2d 0x19 0x2d 0x1a 0x2d 0x1b>;
			mediatek,larbid = <0x2>;
		};

		ptp_od@1100d000 {
			compatible = "mediatek,mt8167-ptp_od";
			interrupts = <0x0 0x53 0x8>;
			linux,phandle = <0x64>;
			phandle = <0x64>;
			reg = <0x0 0x1100d000 0x0 0x1000>;
		};

		pwm@11008000 {
			clock-names = "PWM-main", "PWM1-main", "PWM2-main", "PWM3-main", "PWM4-main", "PWM5-main";
			clocks = <0x5 0x68 0x5 0x69 0x5 0x6a 0x5 0x6b 0x5 0x6c 0x5 0x6d>;
			compatible = "mediatek,mt8167-pwm";
			interrupts = <0x0 0x4c 0x8>;
			linux,phandle = <0x5e>;
			phandle = <0x5e>;
			reg = <0x0 0x11008000 0x0 0x1000>;
		};

		pwrap@1000f000 {
			clock-names = "spi", "wrap";
			clocks = <0x5 0x5e 0x5 0x56>;
			compatible = "mediatek,mt8167-pwrap";
			interrupts = <0x0 0xcc 0x8>;
			linux,phandle = <0xf>;
			phandle = <0xf>;
			reg = <0x0 0x1000f000 0x0 0x1000>;
			reg-names = "pwrap";
			status = "okay";

			mt6392 {
				compatible = "mediatek,mt6392";
				linux,phandle = <0x34>;
				mediatek,system-power-controller;
				phandle = <0x34>;

				mt6392keys {
					compatible = "mediatek,mt6392-keys";
					linux,phandle = <0x35>;
					mediatek,long-press-duration = <0x1>;
					mediatek,long-press-mode = <0x1>;
					mediatek,pwrkey-code = <0x74>;
					phandle = <0x35>;
				};

				mt6392pmic {
					compatible = "mediatek,mt6392-pmic";
					linux,phandle = <0x36>;
					phandle = <0x36>;
				};

				mt6392regulator {
					compatible = "mediatek,mt6392-regulator";
					linux,phandle = <0x37>;
					phandle = <0x37>;

					buck_vcore {
						linux,phandle = <0x2c>;
						phandle = <0x2c>;
						regulator-always-on;
						regulator-boot-on;
						regulator-max-microvolt = <0x149970>;
						regulator-min-microvolt = <0xaae60>;
						regulator-name = "vcore";
						regulator-ramp-delay = <0x30d4>;
					};

					buck_vproc {
						linux,phandle = <0x38>;
						phandle = <0x38>;
						regulator-always-on;
						regulator-boot-on;
						regulator-max-microvolt = <0x149970>;
						regulator-min-microvolt = <0xaae60>;
						regulator-name = "vproc";
						regulator-ramp-delay = <0x30d4>;
					};

					buck_vsys {
						linux,phandle = <0x39>;
						phandle = <0x39>;
						regulator-always-on;
						regulator-boot-on;
						regulator-max-microvolt = <0x2d95ec>;
						regulator-min-microvolt = <0x155cc0>;
						regulator-name = "vsys";
						regulator-ramp-delay = <0x61a8>;
					};

					ldo_vadc18 {
						linux,phandle = <0x3e>;
						phandle = <0x3e>;
						regulator-always-on;
						regulator-boot-on;
						regulator-enable-ramp-delay = <0x108>;
						regulator-max-microvolt = <0x1b7740>;
						regulator-min-microvolt = <0x1b7740>;
						regulator-name = "vadc18";
					};

					ldo_vaud22 {
						linux,phandle = <0x3b>;
						phandle = <0x3b>;
						regulator-always-on;
						regulator-boot-on;
						regulator-enable-ramp-delay = <0x108>;
						regulator-max-microvolt = <0x2191c0>;
						regulator-min-microvolt = <0x1b7740>;
						regulator-name = "vaud22";
					};

					ldo_vaud28 {
						linux,phandle = <0x3d>;
						phandle = <0x3d>;
						regulator-always-on;
						regulator-boot-on;
						regulator-enable-ramp-delay = <0x108>;
						regulator-max-microvolt = <0x2ab980>;
						regulator-min-microvolt = <0x2ab980>;
						regulator-name = "vaud28";
					};

					ldo_vcama {
						linux,phandle = <0x3c>;
						phandle = <0x3c>;
						regulator-enable-ramp-delay = <0x108>;
						regulator-max-microvolt = <0x2ab980>;
						regulator-min-microvolt = <0x2ab980>;
						regulator-name = "vcama";
					};

					ldo_vcamaf {
						linux,phandle = <0x47>;
						phandle = <0x47>;
						regulator-enable-ramp-delay = <0x108>;
						regulator-max-microvolt = <0x325aa0>;
						regulator-min-microvolt = <0x124f80>;
						regulator-name = "vcamaf";
					};

					ldo_vcamd {
						linux,phandle = <0x49>;
						phandle = <0x49>;
						regulator-enable-ramp-delay = <0x108>;
						regulator-max-microvolt = <0x1b7740>;
						regulator-min-microvolt = <0x124f80>;
						regulator-name = "vcamd";
					};

					ldo_vcamio {
						linux,phandle = <0x4a>;
						phandle = <0x4a>;
						regulator-enable-ramp-delay = <0x108>;
						regulator-max-microvolt = <0x1b7740>;
						regulator-min-microvolt = <0x1b7740>;
						regulator-name = "vcamio";
					};

					ldo_vcn18 {
						linux,phandle = <0x46>;
						phandle = <0x46>;
						regulator-enable-ramp-delay = <0x108>;
						regulator-max-microvolt = <0x1b7740>;
						regulator-min-microvolt = <0x1b7740>;
						regulator-name = "vcn18";
					};

					ldo_vcn35 {
						linux,phandle = <0x3f>;
						phandle = <0x3f>;
						regulator-enable-ramp-delay = <0x108>;
						regulator-max-microvolt = <0x36ee80>;
						regulator-min-microvolt = <0x325aa0>;
						regulator-name = "vcn35";
					};

					ldo_vefuse {
						linux,phandle = <0x4c>;
						phandle = <0x4c>;
						regulator-enable-ramp-delay = <0x108>;
						regulator-max-microvolt = <0x1e8480>;
						regulator-min-microvolt = <0x1b7740>;
						regulator-name = "vefuse";
					};

					ldo_vemc3v3 {
						linux,phandle = <0x44>;
						phandle = <0x44>;
						regulator-boot-on;
						regulator-enable-ramp-delay = <0x108>;
						regulator-max-microvolt = <0x325aa0>;
						regulator-min-microvolt = <0x2dc6c0>;
						regulator-name = "vemc3v3";
					};

					ldo_vgp1 {
						linux,phandle = <0x2a>;
						phandle = <0x2a>;
						regulator-enable-ramp-delay = <0x108>;
						regulator-max-microvolt = <0x325aa0>;
						regulator-min-microvolt = <0x124f80>;
						regulator-name = "vgp1";
					};

					ldo_vgp2 {
						linux,phandle = <0x45>;
						phandle = <0x45>;
						regulator-enable-ramp-delay = <0x108>;
						regulator-max-microvolt = <0x325aa0>;
						regulator-min-microvolt = <0x124f80>;
						regulator-name = "vgp2";
					};

					ldo_vio18 {
						linux,phandle = <0x2b>;
						phandle = <0x2b>;
						regulator-always-on;
						regulator-boot-on;
						regulator-enable-ramp-delay = <0x108>;
						regulator-max-microvolt = <0x1b7740>;
						regulator-min-microvolt = <0x1b7740>;
						regulator-name = "vio18";
					};

					ldo_vio28 {
						linux,phandle = <0x40>;
						phandle = <0x40>;
						regulator-always-on;
						regulator-boot-on;
						regulator-enable-ramp-delay = <0x108>;
						regulator-max-microvolt = <0x2ab980>;
						regulator-min-microvolt = <0x2ab980>;
						regulator-name = "vio28";
					};

					ldo_vm {
						linux,phandle = <0x48>;
						phandle = <0x48>;
						regulator-enable-ramp-delay = <0x108>;
						regulator-max-microvolt = <0x1535b0>;
						regulator-min-microvolt = <0x12ebc0>;
						regulator-name = "vm";
					};

					ldo_vm25 {
						linux,phandle = <0x4b>;
						phandle = <0x4b>;
						regulator-enable-ramp-delay = <0x108>;
						regulator-max-microvolt = <0x2625a0>;
						regulator-min-microvolt = <0x2625a0>;
						regulator-name = "vm25";
					};

					ldo_vmc {
						linux,phandle = <0x42>;
						phandle = <0x42>;
						regulator-boot-on;
						regulator-enable-ramp-delay = <0x108>;
						regulator-max-microvolt = <0x325aa0>;
						regulator-min-microvolt = <0x1b7740>;
						regulator-name = "vmc";
					};

					ldo_vmch {
						linux,phandle = <0x43>;
						phandle = <0x43>;
						regulator-boot-on;
						regulator-enable-ramp-delay = <0x108>;
						regulator-max-microvolt = <0x325aa0>;
						regulator-min-microvolt = <0x2dc6c0>;
						regulator-name = "vmch";
					};

					ldo_vusb {
						linux,phandle = <0x41>;
						phandle = <0x41>;
						regulator-always-on;
						regulator-boot-on;
						regulator-enable-ramp-delay = <0x108>;
						regulator-max-microvolt = <0x325aa0>;
						regulator-min-microvolt = <0x325aa0>;
						regulator-name = "vusb";
					};

					ldo_vxo22 {
						linux,phandle = <0x3a>;
						phandle = <0x3a>;
						regulator-always-on;
						regulator-boot-on;
						regulator-enable-ramp-delay = <0x6e>;
						regulator-max-microvolt = <0x2191c0>;
						regulator-min-microvolt = <0x2191c0>;
						regulator-name = "vxo22";
					};
				};

				pinctrl@c000 {
					#gpio-cells = <0x2>;
					compatible = "mediatek,mt6392-pinctrl";
					gpio-controller;
					linux,phandle = <0x4d>;
					phandle = <0x4d>;
					pins-are-numbered;
				};

				typec {
					compatible = "mediatek,mt6392-typec";
					linux,phandle = <0x4e>;
					phandle = <0x4e>;
					status = "disabled";
				};
			};
		};

		scpsys@10006000 {
			#power-domain-cells = <0x1>;
			clock-names = "axi_mfg", "mfg", "mm", "vdec";
			clocks = <0x5 0x82 0x5 0x83 0x5 0x42 0x5 0x7f>;
			compatible = "mediatek,mt8167-scpsys", "syscon";
			infracfg = <0x4>;
			interrupts = <0x0 0x80 0x8 0x0 0x81 0x8 0x0 0x82 0x8 0x0 0x83 0x8>;
			linux,phandle = <0x25>;
			mediatek,pwrap-regmap = <0xf>;
			phandle = <0x25>;
			reg = <0x0 0x10006000 0x0 0x1000>;
		};

		sdio@11170000 {
			clock-names = "source", "hclk";
			clocks = <0x5 0x61 0x5 0xdb>;
			compatible = "mediatek,mt8167-sdio";
			interrupts = <0x0 0x6d 0x8>;
			linux,phandle = <0x6e>;
			phandle = <0x6e>;
			reg = <0x0 0x11170000 0x0 0x1000>;
			status = "disabled";
		};

		smi@14017000 {
			clock-names = "apb", "smi";
			clocks = <0x13 0x0 0x13 0x0>;
			compatible = "mediatek,mt8167-smi-common";
			linux,phandle = <0x26>;
			phandle = <0x26>;
			power-domains = <0x25 0x0>;
			reg = <0x0 0x14017000 0x0 0x1000>;
		};

		spi@1100c000 {
			#address-cells = <0x1>;
			#size-cells = <0x0>;
			clock-names = "parent-clk", "sel-clk", "spi-clk";
			clocks = <0x5 0x1d 0x5 0xc8 0x5 0x59>;
			compatible = "mediatek,mt8167-spi";
			interrupts = <0x0 0x68 0x8>;
			linux,phandle = <0x62>;
			phandle = <0x62>;
			reg = <0x0 0x1100c000 0x0 0x1000>;
			status = "disabled";
		};

		sys_cirq@10202000 {
			compatible = "mediatek,mt8167-sys_cirq", "mediatek,mt6735-sys_cirq", "mediatek,sys_cirq";
			interrupts = <0x0 0xda 0x8>;
			linux,phandle = <0x53>;
			mediatek,cirq_num = <0x93>;
			mediatek,spi_start_offset = <0x48>;
			phandle = <0x53>;
			reg = <0x0 0x10202000 0x0 0x1000>;
		};

		syscfg_pctl_a@10005000 {
			compatible = "mediatek,mt8167-pctl-a-syscfg", "syscon";
			linux,phandle = <0xe>;
			phandle = <0xe>;
			reg = <0x0 0x10005000 0x0 0x1000>;
		};

		systracker@1020b000 {
			compatible = "mediatek,bus_dbg-v2";
			interrupts = <0x0 0x7b 0x8>;
			linux,phandle = <0x54>;
			phandle = <0x54>;
			reg = <0x0 0x1020b000 0x0 0x1000>;
		};

		thermal@1100d000 {
			apmixedsys = <0x6>;
			auxadc = <0x23>;
			clock-names = "therm", "auxadc";
			clocks = <0x5 0x43 0x5 0x5f>;
			compatible = "mediatek,mt8167-thermal";
			infracfg = <0x4>;
			interrupts = <0x0 0x4d 0x8>;
			linux,phandle = <0x63>;
			phandle = <0x63>;
			reg = <0x0 0x1100d000 0x0 0x1000>;
		};

		timer@10008000 {
			clock-names = "clk13m", "clk32k", "bus";
			clocks = <0x5 0x32 0xd 0x5 0x5a>;
			compatible = "mediatek,mt8167-timer", "mediatek,mt6577-timer";
			interrupts = <0x0 0x84 0x8>;
			linux,phandle = <0x32>;
			phandle = <0x32>;
			reg = <0x0 0x10008000 0x0 0x1000>;
		};

		topckgen@10000000 {
			#clock-cells = <0x1>;
			compatible = "mediatek,mt8167-topckgen", "syscon";
			linux,phandle = <0x5>;
			phandle = <0x5>;
			reg = <0x0 0x10000000 0x0 0x1000>;
		};

		toprgu@10007000 {
			#reset-cells = <0x1>;
			compatible = "mediatek,mt8167-wdt", "mediatek,mt6589-wdt";
			interrupts = <0x0 0xc6 0x2>;
			linux,phandle = <0x29>;
			phandle = <0x29>;
			reg = <0x0 0x10007000 0x0 0x1000>;
		};

		touch@ {
			compatible = "mediatek,mt8167-touch", "mediatek,mt8163-touch";
			linux,phandle = <0x8f>;
			phandle = <0x8f>;
			vtouch-supply = <0x2a>;
		};

		uart0@11005000 {
			cell-index = <0x0>;
			clock-div = <0x1>;
			clock-frequency = <0x18cba80>;
			clock-names = "uart0-main", "uart-apdma";
			clocks = <0x5 0x4c 0x5 0x44>;
			compatible = "mediatek,mt8167-uart";
			interrupts = <0x0 0x54 0x8 0x0 0x60 0x8 0x0 0x61 0x8>;
			linux,phandle = <0x5b>;
			phandle = <0x5b>;
			pinctrl-0 = <0x14>;
			pinctrl-1 = <0x15>;
			pinctrl-2 = <0x16>;
			pinctrl-3 = <0x17>;
			pinctrl-4 = <0x18>;
			pinctrl-names = "default", "uart0_rx_set", "uart0_rx_clear", "uart0_tx_set", "uart0_tx_clear";
			reg = <0x0 0x11005000 0x0 0x1000 0x0 0x11000480 0x0 0x80 0x0 0x11000500 0x0 0x80>;
			status = "disabled";
		};

		uart1@11006000 {
			cell-index = <0x1>;
			clock-div = <0x1>;
			clock-frequency = <0x18cba80>;
			clock-names = "uart1-main";
			clocks = <0x5 0x4d>;
			compatible = "mediatek,mt8167-uart", "mediatek,mt6577-uart";
			interrupts = <0x0 0x55 0x8 0x0 0x62 0x8 0x0 0x63 0x8>;
			linux,phandle = <0x5c>;
			phandle = <0x5c>;
			pinctrl-0 = <0x19>;
			pinctrl-1 = <0x1a>;
			pinctrl-2 = <0x1b>;
			pinctrl-3 = <0x1c>;
			pinctrl-4 = <0x1d>;
			pinctrl-names = "default", "uart1_rx_set", "uart1_rx_clear", "uart1_tx_set", "uart1_tx_clear";
			reg = <0x0 0x11006000 0x0 0x1000 0x0 0x11000580 0x0 0x80 0x0 0x11000600 0x0 0x80>;
			status = "disabled";
		};

		uart2@11007000 {
			cell-index = <0x2>;
			clock-div = <0x1>;
			clock-frequency = <0x18cba80>;
			clock-names = "uart2-main";
			clocks = <0x5 0x79>;
			compatible = "mediatek,mt8167-uart";
			interrupts = <0x0 0xd3 0x8 0x0 0x64 0x8 0x0 0x65 0x8>;
			linux,phandle = <0x5d>;
			phandle = <0x5d>;
			pinctrl-0 = <0x1e>;
			pinctrl-1 = <0x1f>;
			pinctrl-2 = <0x20>;
			pinctrl-3 = <0x21>;
			pinctrl-4 = <0x22>;
			pinctrl-names = "default", "uart2_rx_set", "uart2_rx_clear", "uart2_tx_set", "uart2_tx_clear";
			reg = <0x0 0x11007000 0x0 0x1000 0x0 0x11000980 0x0 0x80 0x0 0x11000a00 0x0 0x80>;
			status = "disabled";
		};

		usb@11100000 {
			clock-names = "usbpll", "usbmcu", "usb", "icusb";
			clocks = <0x5 0x28 0x5 0x78 0x5 0x4f 0x5 0x6e>;
			compatible = "mediatek,mt8167-usb20";
			dma = <0x1>;
			dma_channels = <0x8>;
			dyn_fifo = <0x1>;
			iddig_gpio = <0x24 0x29 0x2>;
			interrupts = <0x0 0x48 0x8>;
			linux,phandle = <0x67>;
			mode = <0x2>;
			multipoint = <0x1>;
			num_eps = <0x10>;
			phandle = <0x67>;
			reg = <0x0 0x11100000 0x0 0x10000 0x0 0x11110000 0x0 0x10000>;
			soft_con = <0x1>;
		};

		usb@11190000 {
			cell-index = <0x1>;
			compatible = "mediatek,mt8167-usb11";
			dma = <0x1>;
			dma_channels = <0x4>;
			dyn_fifo = <0x1>;
			interrupts = <0x0 0xd2 0x8>;
			linux,phandle = <0x6f>;
			mode = <0x2>;
			multipoint = <0x1>;
			num_eps = <0x8>;
			phandle = <0x6f>;
			reg = <0x0 0x11190000 0x0 0x10000 0x0 0x11110000 0x0 0x10000>;
			soft_con = <0x1>;
		};

		vdec@16020000 {
			clock-names = "vdec_sel", "normal";
			clocks = <0x5 0xb6 0x5 0x18>;
			compatible = "mediatek,mt8167-vdec";
			interrupts = <0x0 0xb8 0x8>;
			reg = <0x0 0x16020000 0x0 0x10000>;
		};

		vdec_gcon@16000000 {
			clock-names = "apb", "smi";
			clocks = <0x28 0x0 0x28 0x1>;
			compatible = "mediatek,mt8167-vdec_gcon";
			reg = <0x0 0x16000000 0x0 0x10000>;
		};

		vdecsys@16000000 {
			#clock-cells = <0x1>;
			compatible = "mediatek,mt8167-vdecsys", "syscon";
			linux,phandle = <0x28>;
			phandle = <0x28>;
			reg = <0x0 0x16000000 0x0 0x1000>;
		};

		venc@15009000 {
			clock-names = "img_venc";
			clocks = <0x27 0x5>;
			compatible = "mediatek,mt8167-venc";
			interrupts = <0x0 0xb3 0x8>;
			reg = <0x0 0x15009000 0x0 0x1000>;
		};

		vencsys@15000000 {
			#clock-cells = <0x1>;
			compatible = "mediatek,mt8167-vencsys", "syscon";
			linux,phandle = <0x8b>;
			phandle = <0x8b>;
			reg = <0x0 0x15000000 0x0 0x1000>;
			status = "disabled";
		};

		wifi@180f0000 {
			clock-names = "wifi-dma";
			clocks = <0x5 0x44>;
			compatible = "mediatek,wifi";
			interrupts = <0x0 0xc4 0x8>;
			reg = <0x0 0x180f0000 0x0 0x5c>;
		};

		xo@10210000 {
			clock-names = "bsi", "rgbsi";
			clocks = <0x5 0x7a 0x5 0x8c>;
			compatible = "mediatek,mt8167-xo";
			linux,phandle = <0x56>;
			phandle = <0x56>;
			reg = <0x0 0x10210000 0x0 0x1000>;
		};
	};

	timer {
		clock-frequency = <0xc65d40>;
		compatible = "arm,armv8-timer";
		interrupt-parent = <0xc>;
		interrupts = <0x1 0xd 0xf08 0x1 0xe 0xf08 0x1 0xb 0xf08 0x1 0xa 0xf08>;
	};
};
